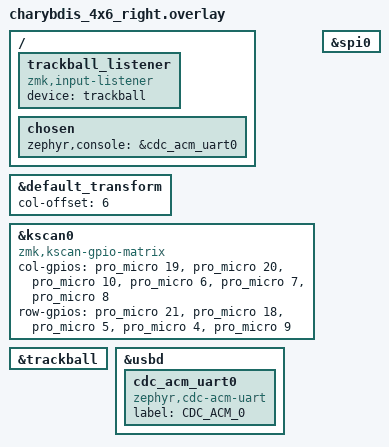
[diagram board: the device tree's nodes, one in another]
/*
 * Copyright (c) 2020 ZMK Contributors
 *
 * SPDX-License-Identifier: MIT
 */
 
#include "charybdis_4x6.dtsi"
#include "charybdis_pmw3610.dtsi"

&default_transform {
	col-offset = <6>;
};


&kscan0 {
	compatible = "zmk,kscan-gpio-matrix";
	col-gpios
		= <&pro_micro 19 (GPIO_ACTIVE_HIGH | GPIO_PULL_DOWN)>
		, <&pro_micro 20 (GPIO_ACTIVE_HIGH | GPIO_PULL_DOWN)>
		, <&pro_micro 10 (GPIO_ACTIVE_HIGH | GPIO_PULL_DOWN)>
		, <&pro_micro 6 (GPIO_ACTIVE_HIGH | GPIO_PULL_DOWN)>
		, <&pro_micro 7 (GPIO_ACTIVE_HIGH | GPIO_PULL_DOWN)>
		, <&pro_micro 8 (GPIO_ACTIVE_HIGH | GPIO_PULL_DOWN)>
		;

	row-gpios
		= <&pro_micro 21  GPIO_ACTIVE_HIGH>
		, <&pro_micro 18  GPIO_ACTIVE_HIGH>
		, <&pro_micro 5  GPIO_ACTIVE_HIGH>
		, <&pro_micro 4  GPIO_ACTIVE_HIGH>
		, <&pro_micro 9 GPIO_ACTIVE_HIGH>
		;
};

&spi0 {
    status = "okay";
};

&trackball {
    status = "okay";
};

// https://github.com/badjeff/zmk-pmw3610-driver
/ {
  trackball_listener {
    compatible = "zmk,input-listener";
    device = <&trackball>;
  };
};
&usbd {
    status = "okay";
    cdc_acm_uart0: cdc_acm_uart0 {
        compatible = "zephyr,cdc-acm-uart";
        label = "CDC_ACM_0";
    };
};

/ {
  chosen {
    zephyr,console = &cdc_acm_uart0;
  };
};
